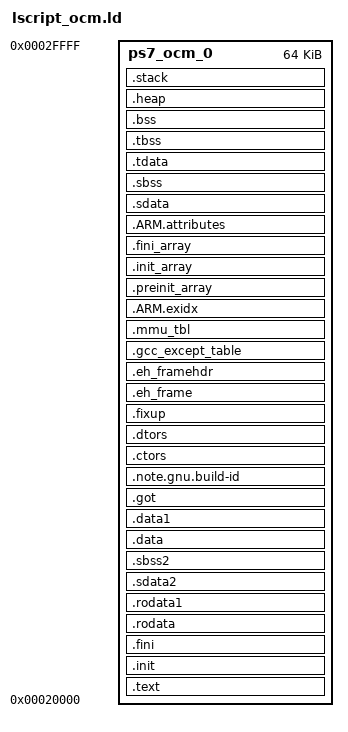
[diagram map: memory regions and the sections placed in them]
/*******************************************************************/
/*                                                                 */
/* This file is automatically generated by linker script generator.*/
/*                                                                 */
/* Version: 2020.2                                                 */
/*                                                                 */
/* Copyright (c) 2010-2019 Xilinx, Inc.  All rights reserved.      */
/*                                                                 */
/* Description : Cortex-A9 Linker Script                           */
/*                                                                 */
/*******************************************************************/

_STACK_SIZE = DEFINED(_STACK_SIZE) ? _STACK_SIZE : 0x2000;
_HEAP_SIZE = DEFINED(_HEAP_SIZE) ? _HEAP_SIZE : 0x2000;

_ABORT_STACK_SIZE = DEFINED(_ABORT_STACK_SIZE) ? _ABORT_STACK_SIZE : 1024;
_SUPERVISOR_STACK_SIZE = DEFINED(_SUPERVISOR_STACK_SIZE) ? _SUPERVISOR_STACK_SIZE : 2048;
_IRQ_STACK_SIZE = DEFINED(_IRQ_STACK_SIZE) ? _IRQ_STACK_SIZE : 1024;
_FIQ_STACK_SIZE = DEFINED(_FIQ_STACK_SIZE) ? _FIQ_STACK_SIZE : 1024;
_UNDEF_STACK_SIZE = DEFINED(_UNDEF_STACK_SIZE) ? _UNDEF_STACK_SIZE : 1024;

/* Define Memories in the system */

MEMORY
{
   /* 只用 OCM 上半区：低 128 KB 被 BootROM 覆盖（只读）。
      ⚠⚠ **LENGTH 原来是 0x00020000（写到 0x3FFFF），那是错的。**
      2026-10-08 上板实测：`dow` 报 `OCM is not enabled at 0x00030000`，
      而 BSP 自己的 `D:/Vitis/rv32_app/src/lscript.ld` 写的是
          ps7_ram_0 : ORIGIN = 0x0, LENGTH = 0x30000
      —— **OCM 只有 192 KB（0x0..0x2FFFF）**。原来那个 LENGTH 多算了 64 KB，
      链接器不报错、上板直接 data abort（栈落在 0x31FD0，一用栈就炸）。
      详见 docs/issues/089。
      ⚠ 改对之后**声学 app（73 KB）就装不下了** —— 那是对的：它本来也跑不起来。
      DDR 路线（`D:/Vitis/rv32_app/src/lscript.ld`）才是规范路线，
      本脚本只适合小 demo。 */
   ps7_ocm_0 : ORIGIN = 0x00020000, LENGTH = 0x00010000
}

/* Specify the default entry point to the program */

ENTRY(_vector_table)

/* Define the sections, and where they are mapped in memory */

SECTIONS
{
.text : {
   KEEP (*(.vectors))
   *(.boot)
   *(.text)
   *(.text.*)
   *(.gnu.linkonce.t.*)
   *(.plt)
   *(.gnu_warning)
   *(.gcc_execpt_table)
   *(.glue_7)
   *(.glue_7t)
   *(.vfp11_veneer)
   *(.ARM.extab)
   *(.gnu.linkonce.armextab.*)
} > ps7_ocm_0

.init : {
   KEEP (*(.init))
} > ps7_ocm_0

.fini : {
   KEEP (*(.fini))
} > ps7_ocm_0

.rodata : {
   __rodata_start = .;
   *(.rodata)
   *(.rodata.*)
   *(.gnu.linkonce.r.*)
   __rodata_end = .;
} > ps7_ocm_0

.rodata1 : {
   __rodata1_start = .;
   *(.rodata1)
   *(.rodata1.*)
   __rodata1_end = .;
} > ps7_ocm_0

.sdata2 : {
   __sdata2_start = .;
   *(.sdata2)
   *(.sdata2.*)
   *(.gnu.linkonce.s2.*)
   __sdata2_end = .;
} > ps7_ocm_0

.sbss2 : {
   __sbss2_start = .;
   *(.sbss2)
   *(.sbss2.*)
   *(.gnu.linkonce.sb2.*)
   __sbss2_end = .;
} > ps7_ocm_0

.data : {
   __data_start = .;
   *(.data)
   *(.data.*)
   *(.gnu.linkonce.d.*)
   *(.jcr)
   *(.got)
   *(.got.plt)
   __data_end = .;
} > ps7_ocm_0

.data1 : {
   __data1_start = .;
   *(.data1)
   *(.data1.*)
   __data1_end = .;
} > ps7_ocm_0

.got : {
   *(.got)
} > ps7_ocm_0

.note.gnu.build-id : {
   KEEP (*(.note.gnu.build-id))
} > ps7_ocm_0

.ctors : {
   __CTOR_LIST__ = .;
   ___CTORS_LIST___ = .;
   KEEP (*crtbegin.o(.ctors))
   KEEP (*(EXCLUDE_FILE(*crtend.o) .ctors))
   KEEP (*(SORT(.ctors.*)))
   KEEP (*(.ctors))
   __CTOR_END__ = .;
   ___CTORS_END___ = .;
} > ps7_ocm_0

.dtors : {
   __DTOR_LIST__ = .;
   ___DTORS_LIST___ = .;
   KEEP (*crtbegin.o(.dtors))
   KEEP (*(EXCLUDE_FILE(*crtend.o) .dtors))
   KEEP (*(SORT(.dtors.*)))
   KEEP (*(.dtors))
   __DTOR_END__ = .;
   ___DTORS_END___ = .;
} > ps7_ocm_0

.fixup : {
   __fixup_start = .;
   *(.fixup)
   __fixup_end = .;
} > ps7_ocm_0

.eh_frame : {
   *(.eh_frame)
} > ps7_ocm_0

.eh_framehdr : {
   __eh_framehdr_start = .;
   *(.eh_framehdr)
   __eh_framehdr_end = .;
} > ps7_ocm_0

.gcc_except_table : {
   *(.gcc_except_table)
} > ps7_ocm_0

.mmu_tbl (ALIGN(16384)) : {
   __mmu_tbl_start = .;
   *(.mmu_tbl)
   __mmu_tbl_end = .;
} > ps7_ocm_0

.ARM.exidx : {
   __exidx_start = .;
   *(.ARM.exidx*)
   *(.gnu.linkonce.armexidix.*.*)
   __exidx_end = .;
} > ps7_ocm_0

.preinit_array : {
   __preinit_array_start = .;
   KEEP (*(SORT(.preinit_array.*)))
   KEEP (*(.preinit_array))
   __preinit_array_end = .;
} > ps7_ocm_0

.init_array : {
   __init_array_start = .;
   KEEP (*(SORT(.init_array.*)))
   KEEP (*(.init_array))
   __init_array_end = .;
} > ps7_ocm_0

.fini_array : {
   __fini_array_start = .;
   KEEP (*(SORT(.fini_array.*)))
   KEEP (*(.fini_array))
   __fini_array_end = .;
} > ps7_ocm_0

.ARM.attributes : {
   __ARM.attributes_start = .;
   *(.ARM.attributes)
   __ARM.attributes_end = .;
} > ps7_ocm_0

.sdata : {
   __sdata_start = .;
   *(.sdata)
   *(.sdata.*)
   *(.gnu.linkonce.s.*)
   __sdata_end = .;
} > ps7_ocm_0

.sbss (NOLOAD) : {
   __sbss_start = .;
   *(.sbss)
   *(.sbss.*)
   *(.gnu.linkonce.sb.*)
   __sbss_end = .;
} > ps7_ocm_0

.tdata : {
   __tdata_start = .;
   *(.tdata)
   *(.tdata.*)
   *(.gnu.linkonce.td.*)
   __tdata_end = .;
} > ps7_ocm_0

.tbss : {
   __tbss_start = .;
   *(.tbss)
   *(.tbss.*)
   *(.gnu.linkonce.tb.*)
   __tbss_end = .;
} > ps7_ocm_0

.bss (NOLOAD) : {
   __bss_start = .;
   *(.bss)
   *(.bss.*)
   *(.gnu.linkonce.b.*)
   *(COMMON)
   __bss_end = .;
} > ps7_ocm_0

_SDA_BASE_ = __sdata_start + ((__sbss_end - __sdata_start) / 2 );

_SDA2_BASE_ = __sdata2_start + ((__sbss2_end - __sdata2_start) / 2 );

/* Generate Stack and Heap definitions */

.heap (NOLOAD) : {
   . = ALIGN(16);
   _heap = .;
   HeapBase = .;
   _heap_start = .;
   . += _HEAP_SIZE;
   _heap_end = .;
   HeapLimit = .;
} > ps7_ocm_0

.stack (NOLOAD) : {
   . = ALIGN(16);
   _stack_end = .;
   . += _STACK_SIZE;
   . = ALIGN(16);
   _stack = .;
   __stack = _stack;
   . = ALIGN(16);
   _irq_stack_end = .;
   . += _IRQ_STACK_SIZE;
   . = ALIGN(16);
   __irq_stack = .;
   _supervisor_stack_end = .;
   . += _SUPERVISOR_STACK_SIZE;
   . = ALIGN(16);
   __supervisor_stack = .;
   _abort_stack_end = .;
   . += _ABORT_STACK_SIZE;
   . = ALIGN(16);
   __abort_stack = .;
   _fiq_stack_end = .;
   . += _FIQ_STACK_SIZE;
   . = ALIGN(16);
   __fiq_stack = .;
   _undef_stack_end = .;
   . += _UNDEF_STACK_SIZE;
   . = ALIGN(16);
   __undef_stack = .;
} > ps7_ocm_0

_end = .;
}

